# SYSCTRL register map
Registers from a debugger description file.
Registers are 32-bit, access not given, no defined reset value unless marked. A register's access mark holds for its fields unless they carry their own. Addresses are absolute; registers are grouped by the start of their names; lines under a group give offsets from that group; [hi:lo] are bit positions; {n}, {i} and the like mark numbered series; 'fields as' and 'values as' point back to an identical list; <NAME> marks a mode.

## CFG
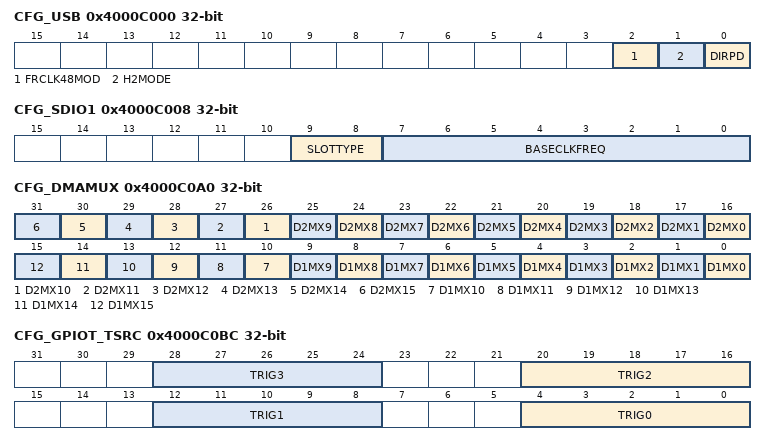
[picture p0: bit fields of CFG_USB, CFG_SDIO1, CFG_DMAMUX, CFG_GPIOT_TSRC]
0x4000C000 CFG_USB
  [2] FRCLK48MOD, [1] H2MODE, [0] DIRPD
0x4000C008 CFG_SDIO1
  [9:8] SLOTTYPE, [7:0] BASECLKFREQ
0x4000C0A0 CFG_DMAMUX
  [n+16] D2MX{n} (n=0..15), [n] D1MX{n} (n=0..15)
0x4000C0A4 CFG_GPIOT_PTEN_1A
  [31:0] PORTEN
0x4000C0B0 CFG_GPIOT_PTEN_1B
  [31:0] PORTEN
0x4000C0B4 CFG_GPIOT_PTEN_2A
  [31:0] PORTEN
0x4000C0B8 CFG_GPIOT_PTEN_2B
  [31:0] PORTEN
0x4000C0BC CFG_GPIOT_TSRC
  [8n+4:8n] TRIG{n} (n=0..3)
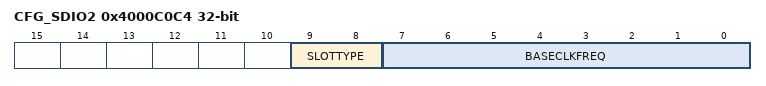
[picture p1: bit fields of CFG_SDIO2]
0x4000C0C4 CFG_SDIO2
  [9:8] SLOTTYPE, [7:0] BASECLKFREQ
0x4000C0D8 CFG_GPIOT_PTEN_3A
  [31:0] PORTEN
0x4000C0DC CFG_GPIOT_PTEN_3B
  [9:0] PORTEN

## SFR
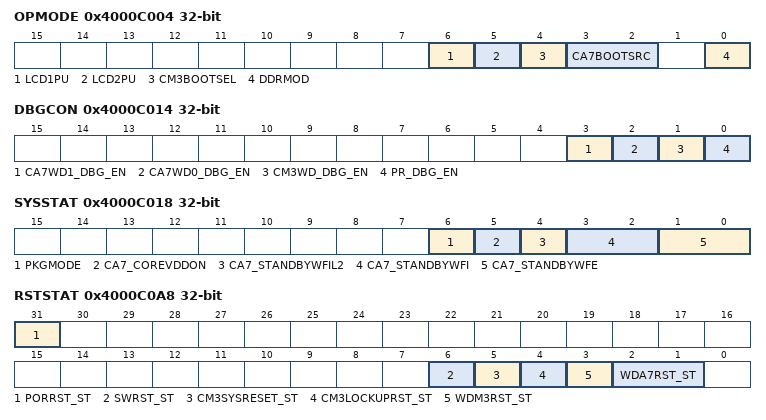
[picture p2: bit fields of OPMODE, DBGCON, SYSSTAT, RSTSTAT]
0x4000C004 OPMODE ro
  [6] LCD1PU, [5] LCD2PU, [4] CM3BOOTSEL, [3:2] CA7BOOTSRC, [0] DDRMOD
0x4000C014 DBGCON
  [3] CA7WD1_DBG_EN, [2] CA7WD0_DBG_EN, [1] CM3WD_DBG_EN, [0] PR_DBG_EN
0x4000C018 SYSSTAT ro
  [6] PKGMODE, [5] CA7_COREVDDON, [4] CA7_STANDBYWFIL2, [3:2] CA7_STANDBYWFI, [1:0] CA7_STANDBYWFE
0x4000C0A8 RSTSTAT ro
  [31] PORRST_ST, [6] SWRST_ST, [5] CM3SYSRESET_ST, [4] CM3LOCKUPRST_ST, [3] WDM3RST_ST, [2:1] WDA7RST_ST
0x4000C0C0 USBSTAT ro
  [0] PLL_LOCK
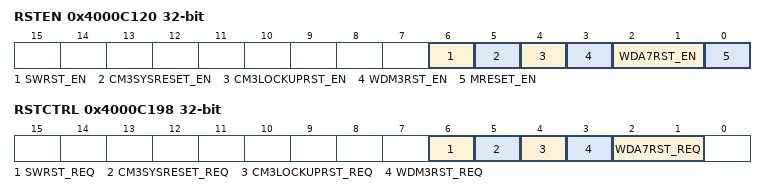
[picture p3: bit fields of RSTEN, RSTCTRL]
0x4000C120 RSTEN
  [6] SWRST_EN, [5] CM3SYSRESET_EN, [4] CM3LOCKUPRST_EN, [3] WDM3RST_EN, [2:1] WDA7RST_EN, [0] MRESET_EN
0x4000C198 RSTCTRL wo
  [6] SWRST_REQ, [5] CM3SYSRESET_REQ, [4] CM3LOCKUPRST_REQ, [3] WDM3RST_REQ, [2:1] WDA7RST_REQ
0x4000C19C VERSION ro
  [8] PROD
0x4000C204 BOOTADDR

## PWRSTAT
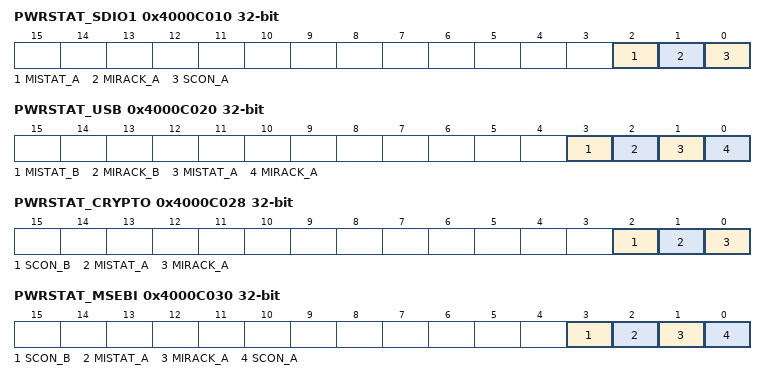
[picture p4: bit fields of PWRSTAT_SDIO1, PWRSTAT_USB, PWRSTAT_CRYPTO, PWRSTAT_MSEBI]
0x4000C010 PWRSTAT_SDIO1 ro
  [2] MISTAT_A, [1] MIRACK_A, [0] SCON_A
0x4000C020 PWRSTAT_USB ro
  [3] MISTAT_B, [2] MIRACK_B, [1] MISTAT_A, [0] MIRACK_A
0x4000C028 PWRSTAT_CRYPTO ro
  [2] SCON_B, [1] MISTAT_A, [0] MIRACK_A
0x4000C030 PWRSTAT_MSEBI ro
  [3] SCON_B, [2] MISTAT_A, [1] MIRACK_A, [0] SCON_A
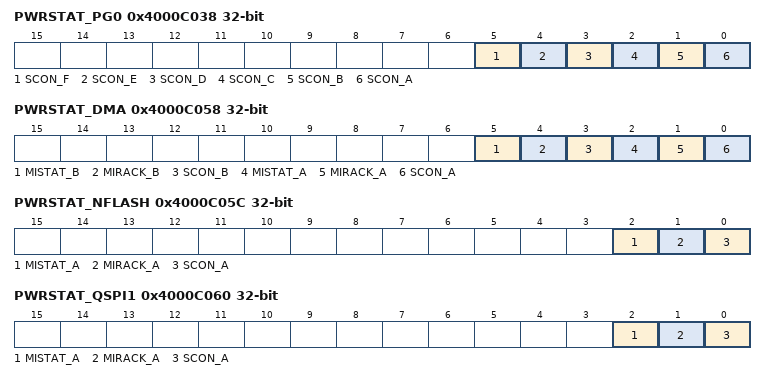
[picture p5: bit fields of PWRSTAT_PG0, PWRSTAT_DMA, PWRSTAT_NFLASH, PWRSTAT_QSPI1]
0x4000C038 PWRSTAT_PG0 ro
  [5] SCON_F, [4] SCON_E, [3] SCON_D, [2] SCON_C, [1] SCON_B, [0] SCON_A
0x4000C058 PWRSTAT_DMA ro
  [5] MISTAT_B, [4] MIRACK_B, [3] SCON_B, [2] MISTAT_A, [1] MIRACK_A, [0] SCON_A
0x4000C05C PWRSTAT_NFLASH ro
  [2] MISTAT_A, [1] MIRACK_A, [0] SCON_A
0x4000C060 PWRSTAT_QSPI1 ro
  [2] MISTAT_A, [1] MIRACK_A, [0] SCON_A
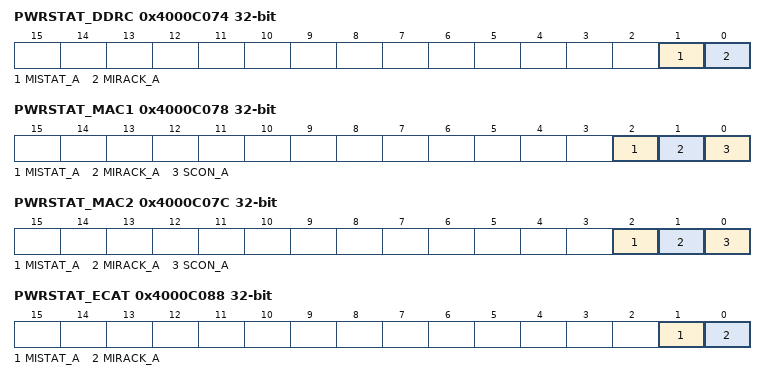
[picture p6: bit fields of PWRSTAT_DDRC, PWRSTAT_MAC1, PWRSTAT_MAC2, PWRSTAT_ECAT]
0x4000C074 PWRSTAT_DDRC ro
  [1] MISTAT_A, [0] MIRACK_A
0x4000C078 PWRSTAT_MAC1 ro
  [2] MISTAT_A, [1] MIRACK_A, [0] SCON_A
0x4000C07C PWRSTAT_MAC2 ro
  [2] MISTAT_A, [1] MIRACK_A, [0] SCON_A
0x4000C088 PWRSTAT_ECAT ro
  [1] MISTAT_A, [0] MIRACK_A
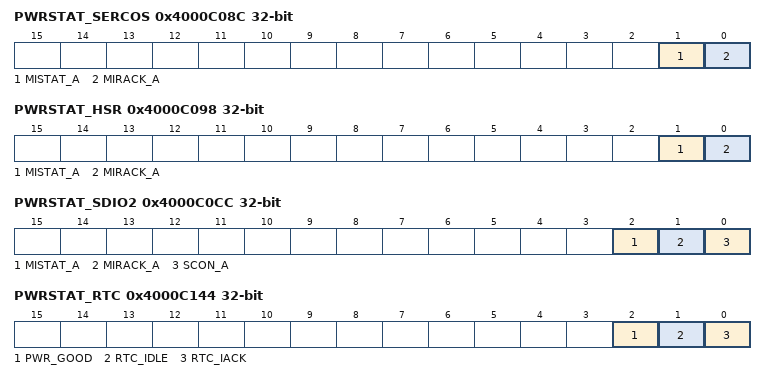
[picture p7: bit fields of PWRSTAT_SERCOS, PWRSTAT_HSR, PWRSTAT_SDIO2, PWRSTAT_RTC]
0x4000C08C PWRSTAT_SERCOS ro
  [1] MISTAT_A, [0] MIRACK_A
0x4000C098 PWRSTAT_HSR ro
  [1] MISTAT_A, [0] MIRACK_A
0x4000C09C PWRSTAT_SWITCH ro
  [0] SCON_A
0x4000C0CC PWRSTAT_SDIO2 ro
  [2] MISTAT_A, [1] MIRACK_A, [0] SCON_A
0x4000C144 PWRSTAT_RTC ro
  [2] PWR_GOOD, [1] RTC_IDLE, [0] RTC_IACK
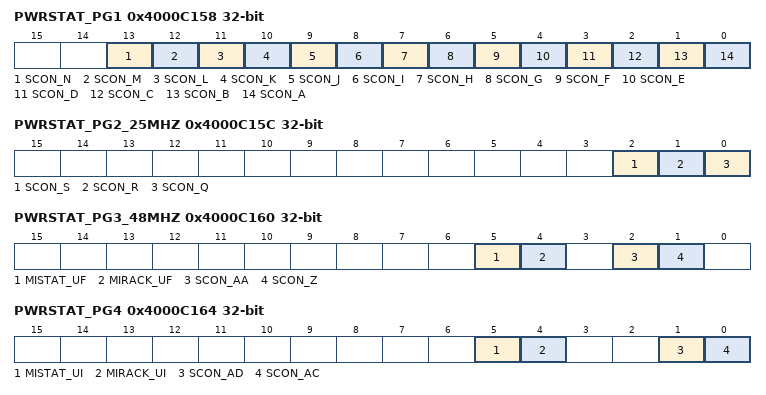
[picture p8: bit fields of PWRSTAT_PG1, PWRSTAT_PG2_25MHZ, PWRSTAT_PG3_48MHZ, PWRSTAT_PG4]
0x4000C158 PWRSTAT_PG1 ro
  [13] SCON_N, [12] SCON_M, [11] SCON_L, [10] SCON_K, [9] SCON_J, [8] SCON_I, [7] SCON_H, [6] SCON_G, [5] SCON_F, [4] SCON_E, [3] SCON_D, [2] SCON_C, [1] SCON_B, [0] SCON_A
0x4000C15C PWRSTAT_PG2_25MHZ ro
  [2] SCON_S, [1] SCON_R, [0] SCON_Q
0x4000C160 PWRSTAT_PG3_48MHZ ro
  [5] MISTAT_UF, [4] MIRACK_UF, [2] SCON_AA, [1] SCON_Z
0x4000C164 PWRSTAT_PG4 ro
  [5] MISTAT_UI, [4] MIRACK_UI, [1] SCON_AD, [0] SCON_AC
0x4000C170 PWRSTAT_ROM ro
  [0] SCON_A
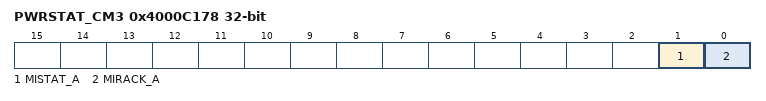
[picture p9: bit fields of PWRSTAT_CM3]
0x4000C178 PWRSTAT_CM3 ro
  [1] MISTAT_A, [0] MIRACK_A
0x4000C17C PWRSTAT_RINCTRL ro
  [0] SCON_A
0x4000C180 PWRSTAT_SWITCHCTRL ro
  [0] SCON_A
